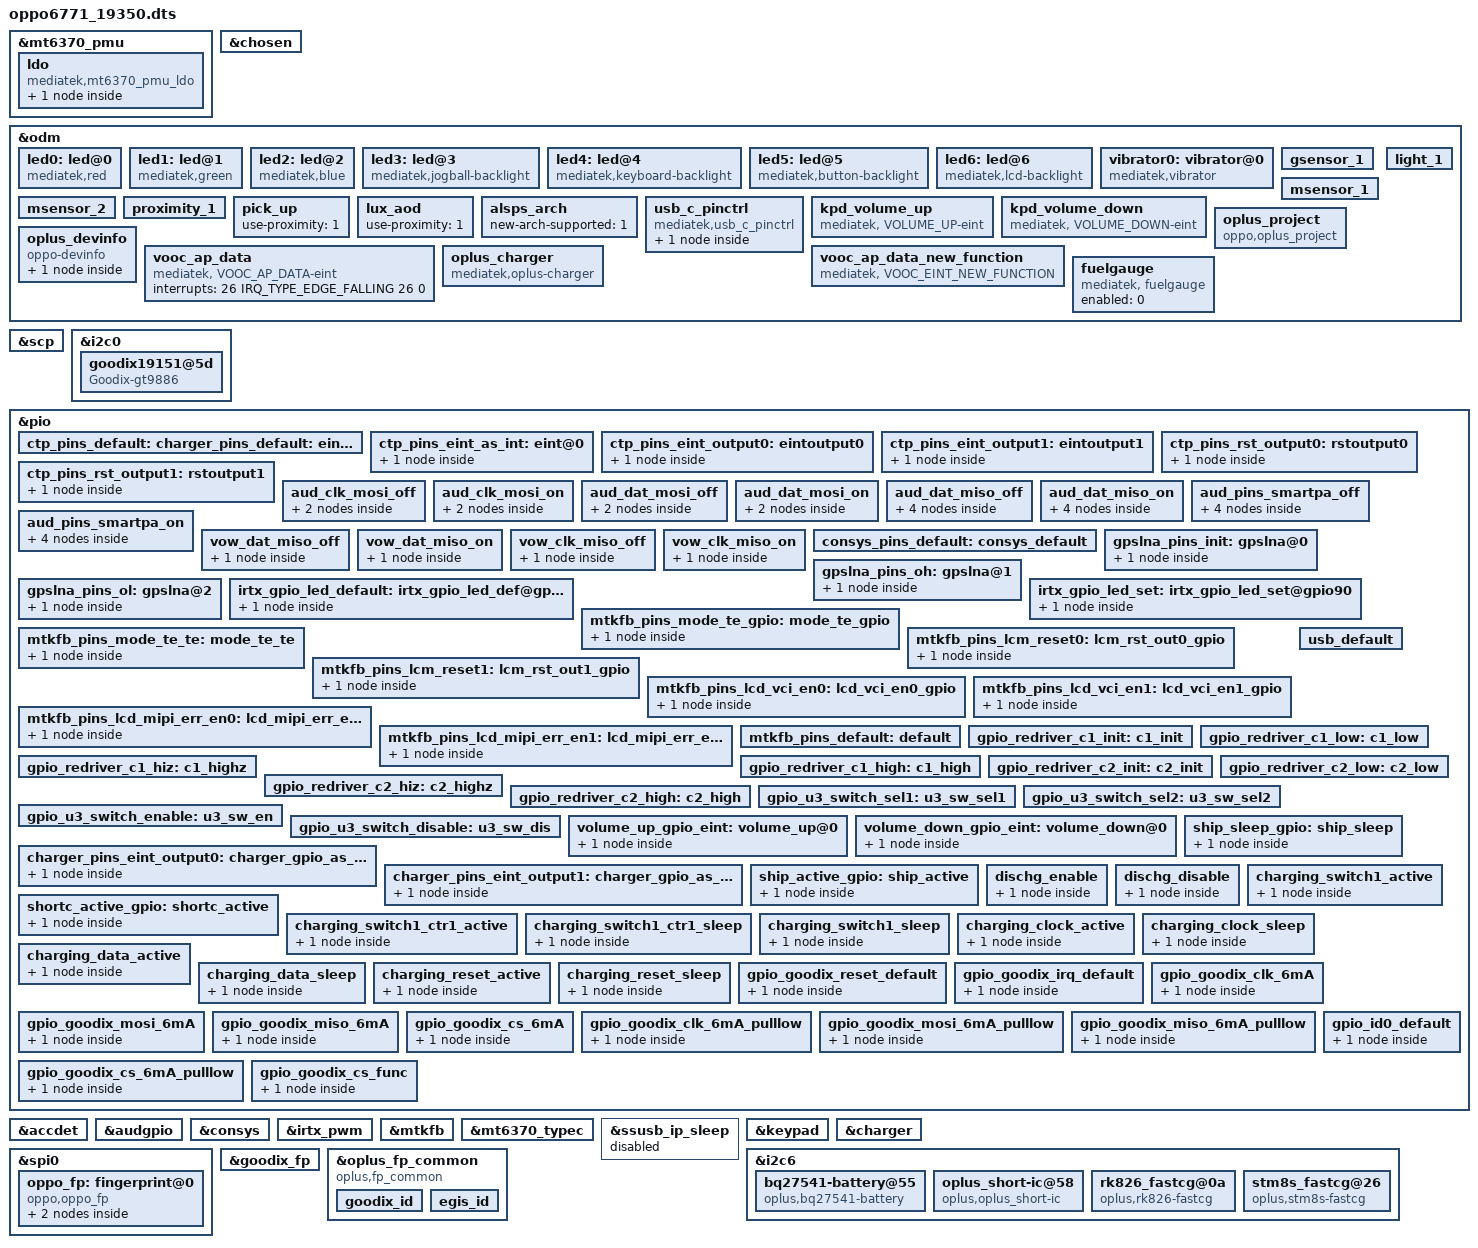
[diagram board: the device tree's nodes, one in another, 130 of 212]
/*
 * Mediatek's mt6771 SoC device tree source
 *
 * Copyright (C) 2016 MediaTek Inc.
 *
 * This program is free software; you can redistribute it and/or modify
 * it under the terms of the GNU General Public License version 2 as
 * published by the Free Software Foundation.
 *
 * This program is distributed in the hope that it will be useful,
 * but WITHOUT ANY WARRANTY; without even the implied warranty of
 * MERCHANTABILITY or FITNESS FOR A PARTICULAR PURPOSE.
 * See http://www.gnu.org/licenses/gpl-2.0.html for more details.
 */
/dts-v1/;
/plugin/;
#include <dt-bindings/interrupt-controller/irq.h>
#include <dt-bindings/interrupt-controller/arm-gic.h>
#include <dt-bindings/pinctrl/mt6771-pinfunc.h>

&mt6370_pmu {
	ldo {
		compatible = "mediatek,mt6370_pmu_ldo";
		interrupt-names = "ldo_oc";
		ldo_oms = <1>; /* 0: floating ; 1: discharge to ground for off mode */
		/* 0:  1 step/16us; 1 : 2 steps/16us; 2: 4 steps/16us; 3: 8steps/16us */
		/*ldo_vrc = <0>; */ /* to assign this  a value will also set en_vrc = 1 */

		ldo_vrc_lt = <1>; /* 0 : disable; 1: 10 us; 2: 20 us; 3: 40 us */
		mt6370_ldo {
			//#ifndef VENDOR_EDIT
			//regulator-name = "irtx_ldo"; /* change name by yourself */
			//#else
			regulator-name = "avdd"; /* for fingerprint*/
			//#endif /*VENDOR_EDIT*/
			regulator-min-microvolt = <3000000>;
			regulator-max-microvolt = <3000000>; /* max == min then apply_uV = 1 */
			/* regulator-microvolt-offset = < 0>; optional*/
			/* regulator-boot-on = "yes"; optional, exist = enabled */
			regulator-always-on = "yes"; /* optional, exist = enabled */
			/* regulator-ramp-delay = <100>; optional*/
		};
	};
};
/* chosen */
&chosen {
	/* fpga may has no lk, we need to specify display info here */
	/* fb buffer is reserved using this dts by memory node above */

	atag,videolfb-fb_base_l = <0x5e605000>;
	atag,videolfb-fb_base_h = <0x0>;
	atag,videolfb-islcmfound = <1>;
	atag,videolfb-islcm_inited = <0>;
	atag,videolfb-fps= <6000>;
	atag,videolfb-vramSize= <0x017bb000>;
	atag,videolfb-lcmname= "nt35595_fhd_dsi_cmd_truly_nt50358_drv";
};

&odm {
//#ifdef VENDOR_EDIT
#include "mediatek/bat_setting/oppo_17197_mt6771_battery_prop_ext.dtsi"
//endif
	led0:led@0 {
		compatible = "mediatek,red";
		led_mode = <0>;
		data = <1>;
		pwm_config = <0 0 0 0 0>;
	};
	led1:led@1 {
		compatible = "mediatek,green";
		led_mode = <0>;
		data = <1>;
		pwm_config = <0 0 0 0 0>;
	};
	led2:led@2 {
		compatible = "mediatek,blue";
		led_mode = <0>;
		data = <1>;
		pwm_config = <0 0 0 0 0>;
	};
	led3:led@3 {
		compatible = "mediatek,jogball-backlight";
		led_mode = <0>;
		data = <1>;
		pwm_config = <0 0 0 0 0>;
	};
	led4:led@4 {
		compatible = "mediatek,keyboard-backlight";
		led_mode = <0>;
		data = <1>;
		pwm_config = <0 0 0 0 0>;
	};
	led5:led@5 {
		compatible = "mediatek,button-backlight";
		led_mode = <0>;
		data = <1>;
		pwm_config = <0 0 0 0 0>;
	};
	led6:led@6 {
		compatible = "mediatek,lcd-backlight";
		/* #ifdef OPLUS_BUG_STABILITY */
		/* led_mode = <5>; */
		/* #else*/
		led_mode = <4>;
		/* #endif */ /* OPLUS_BUG_STABILITY */
		data = <1>;
		pwm_config = <0 1 0 0 0>;
	};
	vibrator0:vibrator@0 {
		compatible = "mediatek,vibrator";
		vib_timer = <30>;
		vib_limit = <0>;
		vib_vol= <11>;
	};
/* sensor start */
	/*
	enum {
		LIS3DH,
		LSM6DS3,
		BMI160,
		LIS2HH12,
		LSM6DSM,
		BMI2XY,
		LSM6DSO,
	};
	*/
	gsensor_1: gsensor_1 {
		status = "okay";
		sensor_name = <2>;//BMI160
		i2c_num = <1>;
		i2c_addr = <0x68>;
		direction = <7>;
		eint_num = <4>;
		step_count_7_en = <0>;
		config_miso = <0>;
		correct_y_bias = <0>;
	};

	/*
	enum {
		AKM09911,
		MMC3530,
		MMC5603,
		MXG4300,
	};
	*/
	msensor_1: msensor_1 {
		status = "okay";
		sensor_name = <1>;//MMC3530
		i2c_num = <1>;
		i2c_addr = <0x30>;
		direction = <2>;
		eint_num = <0>;
		libname = "mmc";
		soft-mag-parameter = <9997 0 103 1 54 0 108 1 1073 0 102 0 548 1 53 1 11493 0>;
	};
	msensor_2: msensor_2 {
		status = "okay";
		sensor_name = <0>;//AKM09911
		i2c_num = <1>;
		i2c_addr = <12>;
		direction = <0>;
		eint_num = <0>;
		libname = "akm";
		soft-mag-parameter = <199 81 100 63 93 113 1 69 217 53 152 58 161 164 1 249
			                       0 75 24 170 194 250 165 135 14 184 11>;
        };
	/*
	enum {
		TMD2725,
		APSD9922,
		STK3335,
		STK3331,
		STK2232,
		TCS3701,
		STK32600,
	};
	*/
	proximity_1: proximity_1 {
		status = "okay";
		sensor_name = <5>;//TCS3701
		i2c_num = <1>;
		i2c_addr = <57>;
		direction = <4>;
		eint_num = <7>;
		low_step = <300>;
		high_step = <400>;
		low_limit = <400>;
		high_limit = <600>;
		dirty_low_step = <180>;
		dirty_high_step = <250>;
		ps_dirty_limit = <1023>;
		ps_ir_limit = <500>;
		ps_adjust_min = <0>;
		ps_adjust_max = <600>;
		sampling_count = <5>;
		step_max = <400>;
		step_min = <110>;
		step_div = <1500>;
		anti_shake_delta = <80>;
		dynamic_cali_max = <1024>;
		raw2offset_radio = <20800>;
		offset_max = <250>;
		offset_range_min = <255>;
		offset_range_max = <255>;
		force_cali_limit = <2000>;
		cali_jitter_limit = <30>;
		cal_offset_margin = <120>;
	};
	light_1: light_1 {
		status = "okay";
		sensor_name = <5>;//TCS3701
		i2c_num = <1>;
		i2c_addr = <57>;
		direction = <4>;
		eint_num = <7>;
		als_ratio = <110>;
		als_type = <2>;
		als_buffer_length =<10>;
		device_name = "tcs3701";
	};
	pick_up: pick_up {
		status = "okay";
		use-proximity = <1>;
	};
	lux_aod: lux_aod {
		status = "okay";
		use-proximity = <1>;
	};
	alsps_arch: alsps_arch {
		status = "okay";
		new-arch-supported = <1>;
	};
/* sensor end */

	usb_c_pinctrl:usb_c_pinctrl {
		compatible = "mediatek,usb_c_pinctrl";
	};

       kpd_volume_up:kpd_volume_up {
               compatible = "mediatek, VOLUME_UP-eint";
               interrupt-parent = <&pio>;
               interrupts = <20 IRQ_TYPE_EDGE_FALLING 20 0>;
               debounce = <32000>;
               status = "okay";
       };

       kpd_volume_down:kpd_volume_down {
               compatible = "mediatek, VOLUME_DOWN-eint";
               interrupt-parent = <&pio>;
               interrupts = <94 IRQ_TYPE_EDGE_FALLING 94 0>;
               debounce = <32000>;
               status = "okay";
       };

	oplus_project:oplus_project {
		compatible = "oppo,oplus_project";
	};
	oplus_devinfo:oplus_devinfo {
		compatible = "oppo-devinfo";

		main-sub {
			compatible = "hw-match, main-sub";
			aboard-patterns = <0 0 0 0>;
			/*main board*/
			//match-projects = <20075 20076>;
		};
	};
	
		//#ifdef VENDOR_EDIT
	vooc_ap_data:vooc_ap_data {
		compatible = "mediatek, VOOC_AP_DATA-eint";
		interrupts = <26 IRQ_TYPE_EDGE_FALLING 26 0>;
	};
	vooc_ap_data_new_function:vooc_ap_data_new_function {
		compatible = "mediatek, VOOC_EINT_NEW_FUNCTION";
	};
	//#endif /*VENDOR_EDIT*/

	oplus_charger: oplus_charger {
		compatible = "mediatek,oplus-charger";
		pinctrl-names = "default", "charger_gpio_as_output_low", "charger_gpio_as_output_high",
				"ship_sleep", "ship_active", "dischg_enable", "dischg_disable";
		pinctrl-0 = <&charger_pins_default>;
		pinctrl-1 = <&charger_pins_eint_output0>;
		pinctrl-2 = <&charger_pins_eint_output1>;
		pinctrl-3 = <&ship_sleep_gpio>;
		pinctrl-4 = <&ship_active_gpio>;
		pinctrl-5 = <&dischg_enable>;
		pinctrl-6 = <&dischg_disable>;
		//pinctrl-5 = <&shortc_active_gpio>;

		//for oplus chg framework:
		qcom,pd_input_current_charger_ma = <3000>;
		qcom,input_current_charger_ma = <2000>;
		qcom,input_current_cdp_ma = <1500>;
		qcom,input_current_usb_ma = <500>;
		qcom,input_current_led_ma = <1200>;
		qcom,input_current_led_ma_forcmcc = <500>;
		qcom,input_current_camera_ma = <1200>;
		qcom,input_current_calling_ma = <1500>;
		qcom,input_current_led_ma_high = <1200>;
		qcom,input_current_led_ma_warm = <1500>;
		qcom,input_current_led_ma_normal = <2000>;
		qcom,led_warm_bat_decidegc = <350>;
		qcom,led_high_bat_decidegc = <370>;

		qcom,iterm_disabled = <0>;
		qcom,iterm_ma = <209>;
		qcom,recharge-mv = <100>;

		qcom,batt_capacity_mah = <4025>; /*typical capacity*/
		//qcom,batt_capacity_mah = <3975>; /*rated capacity*/

		qcom,removed_bat_decidegc = <190>;  /* < -19C */

		qcom,cold_bat_decidegc = <20>;  /* -3C ~ 0C */
		qcom,temp_cold_vfloat_mv = <3980>;
		qcom,temp_cold_fastchg_current_ma = <360>;

		qcom,little_cold_bat_decidegc = <0>;	/* 0C ~ 5C */
		qcom,temp_little_cold_vfloat_mv = <4435>;
		qcom,temp_little_cold_fastchg_current_ma_high = <1850>;
		qcom,temp_little_cold_fastchg_current_ma_low = <1100>;
		qcom,temp_little_cold_fastchg_current_ma = <1100>;
		qcom,pd_temp_little_cold_fastchg_current_ma_high = <1850>;
		qcom,pd_temp_little_cold_fastchg_current_ma_low = <1100>;

		qcom,cool_bat_decidegc = <50>;	/* 5C ~ 12C */
		qcom,temp_cool_vfloat_mv = <4435>;
		qcom,temp_cool_fastchg_current_ma_high = <2200>;
		qcom,temp_cool_fastchg_current_ma_low = <1850>;
		qcom,pd_temp_cool_fastchg_current_ma_high = <2550>;
		qcom,pd_temp_cool_fastchg_current_ma_low = <1850>;

		qcom,little_cool_bat_decidegc = <120>;	/* 12C ~ 16C */
		qcom,temp_little_cool_vfloat_mv = <4435>;
		qcom,temp_little_cool_fastchg_current_ma = <2200>;
		qcom,pd_temp_little_cool_fastchg_current_ma = <3300>;

		qcom,normal_bat_decidegc = <160>;	/* 16C ~ 45C */
		qcom,temp_normal_vfloat_mv = <4435>;
		qcom,temp_normal_fastchg_current_ma = <2200>;
		qcom,pd_temp_normal_fastchg_current_ma = <3300>;

		qcom,warm_bat_decidegc = <450>;		/* 45C ~ 53C */ /*8pin Bat Vooc project need add 3 degree C*/
		qcom,temp_warm_vfloat_mv = <4130>;
		qcom,temp_warm_fastchg_current_ma = <1100>;
		qcom,temp_warm_fastchg_current_ma_led_on = <500>;
		qcom,pd_temp_warm_fastchg_current_ma = <1100>;

		qcom,hot_bat_decidegc = <530>;  /* > 53C */

		qcom,non_standard_vfloat_mv = <3980>;
		qcom,non_standard_fastchg_current_ma = <512>;

		qcom,short_c_bat_cv_mv = <4330>;
		qcom,short_c_bat_vfloat_mv = <3800>;
		qcom,short_c_bat_fastchg_current_ma = <512>;
		qcom,short_c_bat_vfloat_sw_limit = <3750>;

		qcom,cold_vfloat_sw_limit = <3930>;
		qcom,little_cold_vfloat_sw_limit = <4385>;
		qcom,cool_vfloat_sw_limit = <4385>;
		qcom,little_cool_vfloat_sw_limit = <4385>;
		qcom,normal_vfloat_sw_limit = <4385>;
		qcom,warm_vfloat_sw_limit = <4080>;
		qcom,non_standard_vfloat_sw_limit = <3930>;

		qcom,max_chg_time_sec = <36000>;
		qcom,charger_hv_thr = <5800>;
		qcom,charger_lv_thr = <3400>;
		qcom,vbatt_full_thr = <4450>;
		qcom,vbatt_hv_thr = <4550>;
	
		qcom,vfloat_step_mv = <10>;
		qcom,non_standard_vfloat_over_sw_limit = <3990>;
		qcom,cold_vfloat_over_sw_limit = <3990>;
		qcom,little_cold_vfloat_over_sw_limit = <4445>;
		qcom,cool_vfloat_over_sw_limit = <4445>;
		qcom,little_cool_vfloat_over_sw_limit = <4445>;
		qcom,normal_vfloat_over_sw_limit = <4445>;
		qcom,warm_vfloat_over_sw_limit = <4140>;

		qcom,vbatt_power_off = <3300>;
		qcom,vbatt_soc_1 = <3410>;
		qcom,vooc_project = <1>;
		qcom,vbatt_num = <1>;

		qcom,normal_vterm_hw_inc = <13>;
		qcom,non_normal_vterm_hw_inc = <13>;

		qcom,ff1_normal_fastchg_ma = <1500>;
		qcom,ff1_warm_fastchg_ma = <1500>;
		qcom,ffc2_normal_fastchg_ma = <1100>;/*12C~35c*/
		qcom,ffc2_warm_fastchg_ma = <1200>;/*35C~40c*/
		qcom,ffc2_temp_warm_decidegc = <350>;
		qcom,ffc2_temp_high_decidegc = <400>;
		qcom,ffc2_temp_low_decidegc = <120>;
		qcom,ff1_exit_step_ma = <600>;
		qcom,ff1_warm_exit_step_ma = <500>;
		qcom,ffc2_exit_step_ma = <200>;
		qcom,ffc2_warm_exit_step_ma = <200>;

		qcom,ffc_normal_vfloat_sw_limit = <4475>;
		qcom,ffc2_normal_vfloat_sw_limit = <4475>;
		qcom,ffc_temp_normal_vfloat_mv = <4550>;
		qcom,ffc_normal_vfloat_over_sw_limit = <4550>;

		qcom,default_iterm_ma = <209>;
		qcom,default_temp_normal_fastchg_current_ma = <2200>;
		qcom,default_normal_vfloat_sw_limit = <4385>;
		qcom,default_temp_normal_vfloat_mv = <4435>;
		qcom,default_normal_vfloat_over_sw_limit = <4445>;

		//for 2nd chip:
		qcom,iterm_ma_2nd = <300>;
		qcom,recharge-mv_2nd = <121>;

		qcom,temp_little_cold_vfloat_mv_2nd = <4391>;	/* 0C ~ 5C */
		qcom,temp_cool_vfloat_mv_2nd = <4391>;	/* 5C ~ 12C */
		qcom,temp_little_cool_vfloat_mv_2nd = <4391>;	/* 12C ~ 16C */
		qcom,temp_normal_vfloat_mv_2nd = <4391>;	/* 16C ~ 45C */

		qcom,little_cold_vfloat_over_sw_limit_2nd = <4395>;
		qcom,cool_vfloat_over_sw_limit_2nd = <4395>;
		qcom,little_cool_vfloat_over_sw_limit_2nd = <4395>;
		qcom,normal_vfloat_over_sw_limit_2nd = <4445>;

		qcom,default_iterm_ma_2nd = <300>;
		qcom,default_temp_normal_vfloat_mv_2nd = <4391>;
		qcom,default_normal_vfloat_over_sw_limit_2nd = <4445>;

		//for control:
		//qcom,suspend_after_full;
		qcom,check_batt_full_by_sw;
		qcom,external_gauge;
		qcom,chg_ctrl_by_calling;
		qcom,chg_ctrl_by_lcd;
		qcom,chg_ctrl_by_camera;
		qcom,sw_vfloat_over_protect_enable;
		qcom,ffc_support;

		//GPIO config:
		qcom,chargerid_switch-gpio = <&pio 97 0x00>;
		qcom,ship-gpio = <&pio 155 0x00>;
		qcom,dischg-gpio = <&pio 17 0x00>;
		//qcom,shortc-gpio = <&pio 77 0x00>;
	};
	
//#ifdef VENDOR_EDIT
	fuelgauge: fuelgauge {
		compatible = "mediatek, fuelgauge";
	};
//#endif
};

&scp {
	core_1 = "enable";
	scp_sramSize = <0x00080000>;     /* scp_A_sram_size */
};
//#ifdef OPLUS_FEATURE_TP_BASIC
&i2c0 {
	status = "okay";
	goodix19151@5d {
		compatible = "Goodix-gt9886";
		reg = <0x5d>;
		chip-name = "GT9886";

		/* Interrupt && Irq-gpio */
		//interrupt-parent = <&tlmm>;
		//interrupts = <1 0x2002>;
		interrupt-parent = <&pio>;
		interrupts = <1 IRQ_TYPE_EDGE_FALLING 1 0>;

		/* Power Config */
		enable2v8_gpio = <&pio 159 0x1>;
		//vdd_2v8-supply = <&mt_pmic_vmch_ldo_reg>;
		//vcc_1v8-supply = <&pm660_l14>;
		//vdd_2v8_volt = <2950000>;

		/* Other HW Resource */
		//irq-gpio = <&tlmm 1 0x2008>;
		irq-gpio = <&pio 1 0x2002>;
		//reset-gpio = <&tlmm 58 0x1>;
		reset-gpio = <&pio 150 0>;
		pinctrl-names = "default";
		//pinctrl-0 = <&ts_int_active &ts_reset_active>;

		vid_len = <2>;
		tp_type = <8>;
		// type of tp_dev ,TP-SAMSUNG = 8;
		platform_support_project = <19350 19352 19355>;
		platform_support_project_dir = <19151 19151 19151>;
		platform_support_project_commandline = "default_commandline", "default_commandline", "default_commandline";

		touchpanel,max-num-support = <10>;
		touchpanel,tx-rx-num = <15 34>;
		touchpanel,panel-coords = <1080 2400>;
		touchpanel,display-coords = <1080 2400>;
		touchpanel,touchmajor-limit = <0 54>;

		/* SW Support Feature Control */
		register-is-16bit;
		black_gesture_support;
		single_tap_support;
		fw_edge_limit_support;
		pressure_report_support;
		charger_pump_support;
		game_switch_support;
		smart_gesture_support;
		fw_update_app_support;
		fingerprint_underscreen_support;
		esd_handle_support;
		/*
		 *Virtual Key Config:
		 *1:touchpanel,button-type: <virtualkey_type  supportted_button-map>
		 *virtualkey_type:
		 *Type 1: using board_properties
		 *Type 2: using same IC (button zone&& touch zone are seprate)
		 *Type 3: using diffrent IC (button zone&& touch zone are seprate)
		 *Type 4: No need of virtual key process
		 *supportted_button-map:select|menu|home|back
		 *
		 *2:touchpanel,button-map
		 *type (X1,Y1)(X2,Y2)(X3,Y3)(Width_X,Hight_Y)--Only when button-type is 0
		 */
		touchpanel,button-type = <4>;
		touchpanel.button-TRx = <0 0>;
	};
};
//#endif
/* TOUCH start */
/*&touch {
	tpd-resolution = <1080 1920>;
	use-tpd-button = <0>;
	tpd-key-num = <3>;
	tpd-key-local= <139 172 158 0>;
	tpd-key-dim-local = <90 883 100 40 230 883 100 40 370 883 100 40 0 0 0 0>;
	tpd-max-touch-num = <5>;
	tpd-filter-enable = <1>;
	tpd-filter-pixel-density = <146>;
	tpd-filter-custom-prameters = <0 0 0 0 0 0 0 0 0 0 0 0>;
	tpd-filter-custom-speed = <0 0 0>;
	pinctrl-names = "default", "state_eint_as_int",
		"state_eint_output0", "state_eint_output1",
		"state_rst_output0", "state_rst_output1";
	pinctrl-0 = <&ctp_pins_default>;
	pinctrl-1 = <&ctp_pins_eint_as_int>;
	pinctrl-2 = <&ctp_pins_eint_output0>;
	pinctrl-3 = <&ctp_pins_eint_output1>;
	pinctrl-4 = <&ctp_pins_rst_output0>;
	pinctrl-5 = <&ctp_pins_rst_output1>;
	status = "okay";
};*/
&pio {
	ctp_pins_default: eint0default {
	};
	ctp_pins_eint_as_int: eint@0 {
		pins_cmd_dat {
			pinmux = <PINMUX_GPIO1__FUNC_GPIO1>;
			slew-rate = <0>;
			bias-disable;
		};
	};
	ctp_pins_eint_output0: eintoutput0 {
		pins_cmd_dat {
			pinmux = <PINMUX_GPIO1__FUNC_GPIO1>;
			slew-rate = <1>;
			output-low;
		};
	};
	ctp_pins_eint_output1: eintoutput1 {
		pins_cmd_dat {
			pinmux = <PINMUX_GPIO1__FUNC_GPIO1>;
			slew-rate = <1>;
			output-high;
		};
	};
	ctp_pins_rst_output0: rstoutput0 {
		pins_cmd_dat {
			pinmux = <PINMUX_GPIO2__FUNC_GPIO2>;
			slew-rate = <1>;
			output-low;
		};
	};
	ctp_pins_rst_output1: rstoutput1 {
		pins_cmd_dat {
			pinmux = <PINMUX_GPIO2__FUNC_GPIO2>;
			slew-rate = <1>;
			output-high;
		};
	};
};
/* TOUCH end */

/* accdet start */
&accdet {
	/* accdet micbias voltage: 0x07,2.7v;0x05,2.5v;0x02,1.9v */
	accdet-mic-vol = <6>;
	headset-mode-setting = <0x500 0x500 1 0x1f0 0x800 0x800 0x20 0x44>;
	accdet-plugout-debounce = <1>;
	/*1:ACC mode, 2:low cost without in bias, 6:low cost with in bias*/
	accdet-mic-mode = <1>;
	/* eint_level_trigger: 8,LEVEL_LOW(default);4,LEVEL_HIGH;others,LEVEL_LOW */
	headset-eint-level-pol = <8>;
	/*0--MD_MAX--UP_MAX--DW_MAX*/
	headset-three-key-threshold = <0 80 220 400>;
	headset-three-key-threshold-CDD = <0 121 192 600>;
	/*0--MD_MAX--VOICE_MAX--UP_MAX--DW_MAX*/
	headset-four-key-threshold = <0 58 121 192 400>;
	status = "okay";
};
/* accdet end */

/* AUDIO GPIO standardization */
&audgpio {
	pinctrl-names = "aud_clk_mosi_off",
			"aud_clk_mosi_on",
			"aud_dat_mosi_off",
			"aud_dat_mosi_on",
			"aud_dat_miso_off",
			"aud_dat_miso_on",
			"aud_smartpa_off",
			"aud_smartpa_on",
			"vow_dat_miso_off",
			"vow_dat_miso_on",
			"vow_clk_miso_off",
			"vow_clk_miso_on";
	pinctrl-0 = <&aud_clk_mosi_off>;
	pinctrl-1 = <&aud_clk_mosi_on>;
	pinctrl-2 = <&aud_dat_mosi_off>;
	pinctrl-3 = <&aud_dat_mosi_on>;
	pinctrl-4 = <&aud_dat_miso_off>;
	pinctrl-5 = <&aud_dat_miso_on>;
	pinctrl-6 = <&aud_pins_smartpa_off>;
	pinctrl-7 = <&aud_pins_smartpa_on>;
	pinctrl-8 = <&vow_dat_miso_off>;
	pinctrl-9 = <&vow_dat_miso_on>;
	pinctrl-10 = <&vow_clk_miso_off>;
	pinctrl-11 = <&vow_clk_miso_on>;
	status = "okay";
};

&pio {
	aud_clk_mosi_off: aud_clk_mosi_off {
		pins_cmd0_dat {
			pinmux = <PINMUX_GPIO136__FUNC_GPIO136>;
			input-enable;
			bias-pull-down;
		};
		pins_cmd1_dat {
			pinmux = <PINMUX_GPIO137__FUNC_GPIO137>;
			input-enable;
			bias-pull-down;
		};
	};

	aud_clk_mosi_on: aud_clk_mosi_on {
		pins_cmd0_dat {
			pinmux = <PINMUX_GPIO136__FUNC_AUD_CLK_MOSI>;
			input-schmitt-enable;
			bias-disable;
		};
		pins_cmd1_dat {
			pinmux = <PINMUX_GPIO137__FUNC_AUD_SYNC_MOSI>;
			input-schmitt-enable;
			bias-disable;
		};
	};

	aud_dat_mosi_off: aud_dat_mosi_off {
		pins_cmd0_dat {
			pinmux = <PINMUX_GPIO138__FUNC_GPIO138>;
			input-enable;
			bias-disable;
		};
		pins_cmd1_dat {
			pinmux = <PINMUX_GPIO139__FUNC_GPIO139>;
			input-enable;
			bias-pull-down;
		};
	};

	aud_dat_mosi_on: aud_dat_mosi_on {
		pins_cmd0_dat {
			pinmux = <PINMUX_GPIO138__FUNC_AUD_DAT_MOSI0>;
			input-schmitt-enable;
			bias-disable;
		};
		pins_cmd1_dat {
			pinmux = <PINMUX_GPIO139__FUNC_AUD_DAT_MOSI1>;
			input-schmitt-enable;
			bias-disable;
		};
	};

	aud_dat_miso_off: aud_dat_miso_off {
		pins_cmd0_dat {
			pinmux = <PINMUX_GPIO140__FUNC_GPIO140>;
			input-enable;
			bias-disable;
		};
		pins_cmd1_dat {
			pinmux = <PINMUX_GPIO141__FUNC_GPIO141>;
			input-enable;
			bias-disable;
		};
		pins_cmd2_dat {
			pinmux = <PINMUX_GPIO142__FUNC_GPIO142>;
			input-enable;
			bias-disable;
		};
		pins_cmd3_dat {
			pinmux = <PINMUX_GPIO143__FUNC_GPIO143>;
			input-enable;
			bias-disable;
		};
	};

	aud_dat_miso_on: aud_dat_miso_on {
		pins_cmd0_dat {
			pinmux = <PINMUX_GPIO140__FUNC_AUD_CLK_MISO>;
			input-schmitt-enable;
			bias-disable;
		};
		pins_cmd1_dat {
			pinmux = <PINMUX_GPIO141__FUNC_AUD_SYNC_MISO>;
			input-schmitt-enable;
			bias-disable;
		};
		pins_cmd2_dat {
			pinmux = <PINMUX_GPIO142__FUNC_AUD_DAT_MISO0>;
			input-schmitt-enable;
			bias-disable;
		};
		pins_cmd3_dat {
			pinmux = <PINMUX_GPIO143__FUNC_AUD_DAT_MISO1>;
			input-schmitt-enable;
			bias-disable;
		};
	};

	aud_pins_smartpa_off: aud_pins_smartpa_off {
		pins_cmd0_dat {
			pinmux = <PINMUX_GPIO174__FUNC_GPIO174>;
		};
		pins_cmd1_dat {
			pinmux = <PINMUX_GPIO170__FUNC_GPIO170>;
		};
		pins_cmd2_dat {
			pinmux = <PINMUX_GPIO171__FUNC_GPIO171>;
		};
		pins_cmd3_dat {
			pinmux = <PINMUX_GPIO172__FUNC_GPIO172>;
		};
	};

	aud_pins_smartpa_on: aud_pins_smartpa_on {
		pins_cmd0_dat {
			pinmux = <PINMUX_GPIO174__FUNC_I2S0_DI>;
		};
		pins_cmd1_dat {
			pinmux = <PINMUX_GPIO170__FUNC_I2S3_BCK>;
		};
		pins_cmd2_dat {
			pinmux = <PINMUX_GPIO171__FUNC_I2S3_LRCK>;
		};
		pins_cmd3_dat {
			pinmux = <PINMUX_GPIO172__FUNC_I2S3_DO>;
		};
	};

	vow_dat_miso_off: vow_dat_miso_off {
		pins_cmd1_dat {
			pinmux = <PINMUX_GPIO142__FUNC_GPIO142>;
			input-enable;
			bias-pull-down;
		};
	};

	vow_dat_miso_on: vow_dat_miso_on {
		pins_cmd1_dat {
			pinmux = <PINMUX_GPIO142__FUNC_VOW_DAT_MISO>;
			input-schmitt-enable;
			bias-disable;
		};
	};

	vow_clk_miso_off: vow_clk_miso_off {
		pins_cmd3_dat {
			pinmux = <PINMUX_GPIO143__FUNC_GPIO143>;
			input-enable;
			bias-pull-down;
		};
	};

	vow_clk_miso_on: vow_clk_miso_on {
		pins_cmd3_dat {
			pinmux = <PINMUX_GPIO143__FUNC_VOW_CLK_MISO>;
			input-schmitt-enable;
			bias-disable;
		};
	};
};
/* AUDIO end */

/* CONSYS GPIO standardization */
&pio {
	consys_pins_default: consys_default {
	};
	gpslna_pins_init: gpslna@0 {
		pins_cmd_dat {
			pinmux = <PINMUX_GPIO169__FUNC_GPIO169>;
			//#ifndef VENDOR_EDIT
			//modify for: [GPS_LNA gpio's output direction is out]
			/*
			slew-rate = <0>;
			*/
			//#else /* VENDOR_EDIT */
			slew-rate = <1>;
			//#endif /* VENDOR_EDIT */
			bias-disable;
			output-low;
		};
	};
	gpslna_pins_oh: gpslna@1 {
		pins_cmd_dat {
			pinmux = <PINMUX_GPIO169__FUNC_GPIO169>;
			slew-rate = <1>;
			output-high;
		};
	};
	gpslna_pins_ol: gpslna@2 {
		pins_cmd_dat {
			pinmux = <PINMUX_GPIO169__FUNC_GPIO169>;
			slew-rate = <1>;
			output-low;
		};
	};
};
&consys {
	pinctrl-names = "default", "gps_lna_state_init", "gps_lna_state_oh", "gps_lna_state_ol";
	pinctrl-0 = <&consys_pins_default>;
	pinctrl-1 = <&gpslna_pins_init>;
	pinctrl-2 = <&gpslna_pins_oh>;
	pinctrl-3 = <&gpslna_pins_ol>;
	status = "okay";
};
/* CONSYS end */

/* IRTX GPIO Start */
&irtx_pwm {
	pinctrl-names = "irtx_gpio_led_default", "irtx_gpio_led_set";
	pinctrl-0 = <&irtx_gpio_led_default>;
	pinctrl-1 = <&irtx_gpio_led_set>;
	status = "okay";
};
&pio {
	/* IRTX GPIO Settings -Start */
	/* default: GPIO0, output, high */
	irtx_gpio_led_default:irtx_gpio_led_def@gpio90 {
		pins_cmd_dat {
			pinmux = <PINMUX_GPIO90__FUNC_GPIO90>;
			slew-rate = <1>;
			bias-disable;
			output-low;
			input-schmitt-enable = <0>;
		};
	};

	irtx_gpio_led_set:irtx_gpio_led_set@gpio90 {
		pins_cmd_dat {
			pinmux = <PINMUX_GPIO90__FUNC_PWM_A>;
			slew-rate = <1>;
			output-high;
		};
	};
}; /* IRTX GPIO Settings -End */


/* #ifdef OPLUS_BUG_STABILITY */
&pio {
	mtkfb_pins_mode_te_gpio: mode_te_gpio {
		pins_cmd_dat {
			pinmux = <PINMUX_GPIO44__FUNC_GPIO44>;
	};
		};

	mtkfb_pins_mode_te_te: mode_te_te {
		pins_cmd_dat {
			pinmux = <PINMUX_GPIO44__FUNC_DSI_TE>;
		};
	};

	mtkfb_pins_lcm_reset0: lcm_rst_out0_gpio {
		pins_cmd_dat {
			pinmux = <PINMUX_GPIO45__FUNC_GPIO45>;
			slew-rate = <1>;
			output-low;
		};
	};

	mtkfb_pins_lcm_reset1: lcm_rst_out1_gpio {
		pins_cmd_dat {
			pinmux = <PINMUX_GPIO45__FUNC_GPIO45>;
			slew-rate = <1>;
			output-high;
		};
	};

	mtkfb_pins_lcd_vci_en0: lcd_vci_en0_gpio {
		pins_cmd_dat {
			pinmux = <PINMUX_GPIO46__FUNC_GPIO46>;
			slew-rate = <1>;
			output-low;
		};
	};

	mtkfb_pins_lcd_vci_en1: lcd_vci_en1_gpio {
		pins_cmd_dat {
			pinmux = <PINMUX_GPIO46__FUNC_GPIO46>;
			slew-rate = <1>;
			output-high;
		};
	};

	mtkfb_pins_lcd_mipi_err_en0: lcd_mipi_err_en0_gpio {
		pins_cmd_dat {
			pinmux = <PINMUX_GPIO9__FUNC_GPIO9>;
			slew-rate = <1>;
			output-low;
		};
	};

	mtkfb_pins_lcd_mipi_err_en1: lcd_mipi_err_en1_gpio {
		pins_cmd_dat {
			pinmux = <PINMUX_GPIO9__FUNC_GPIO9>;
			slew-rate = <1>;
			output-high;
		};
	};


	mtkfb_pins_default: default {
};
};

&mtkfb {
	pinctrl-names = "default", "mode_te_gpio", "mode_te_te", "lcm_rst_out0_gpio",
	"lcm_rst_out1_gpio", "lcd_vci_en0_gpio", "lcd_vci_en1_gpio",
	"lcd_mipi_err_en0_gpio", "lcd_mipi_err_en1_gpio";
	pinctrl-0 = <&mtkfb_pins_default>;
	pinctrl-1 = <&mtkfb_pins_mode_te_gpio>;
	pinctrl-2 = <&mtkfb_pins_mode_te_te>;
	pinctrl-3 = <&mtkfb_pins_lcm_reset0>;
	pinctrl-4 = <&mtkfb_pins_lcm_reset1>;
	pinctrl-5 = <&mtkfb_pins_lcd_vci_en0>;
	pinctrl-6 = <&mtkfb_pins_lcd_vci_en1>;
	pinctrl-7 = <&mtkfb_pins_lcd_mipi_err_en0>;
	pinctrl-8 = <&mtkfb_pins_lcd_mipi_err_en1>;
	status = "okay";
	oppo_display_elevenbits_support;
};
//#ifdef VENDOR_EDIT
&fuelgauge{
	enabled = <0>;
};
//#endif

//#ifdef VENDOR_EDIT
/*&i2c5 {

	bq25601d-charger@6b {
		status = "okay";
		compatible = "oplus,bq25601d-charger";
		reg = <0x6b>;
		chip-name = "BQ25601D";
		interrupt-parent = <&pio>;
		interrupts = <91 IRQ_TYPE_EDGE_FALLING 91 0>;
		chg-irq-gpio = <&pio 91 0x2002>;
	};

	bq25890h-charger@6a {
		status = "okay";
		compatible = "oplus,bq25890h-charger";
		reg = <0x6a>;
		chip-name = "BQ25890H";
		interrupt-parent = <&pio>;
		interrupts = <91 IRQ_TYPE_EDGE_FALLING 91 0>;
		chg-irq-gpio = <&pio 91 0x2002>;
	};
};*/
&mt6370_pmu {
//#ifdef VENDOR_EDIT
	//mt6370,intr_gpio_num = <10>; /* direct defined GPIO num */
	//mt6370,intr_gpio = <&pio 10 0x0>;
//#else
	mt6370,intr_gpio_num = <91>; /* direct defined GPIO num */
	mt6370,intr_gpio = <&pio 91 0x0>;
//#endif
};

&mt6370_typec {
	mt6370pd,intr_gpio_num = <41>; /* direct defined GPIO num */
	mt6370pd,intr_gpio = <&pio 41 0x0>;
//#ifdef VENDOR_EDIT
	mt-tcpc,role_def = <0>;
//#endif
};

//#ifdef VENDOR_EDIT
&ssusb_ip_sleep {
	status = "disabled";
};
//#endif /*VENDOR_EDIT*/

/* USB TYPEC GPIO start */
&pio {
	usb_default: usb_default {
	};
/*
	gpio_redriver_c1_init: c1_init {
		pins_cmd_dat {
			pinmux = <PINMUX_GPIO18__FUNC_GPIO18>;
			slew-rate = <1>;
			output-low;
		};
	};

	gpio_redriver_c1_low: c1_low {
		pins_cmd_dat {
			pinmux = <PINMUX_GPIO18__FUNC_GPIO18>;
			slew-rate = <1>;
			output-low;
		};
	};

	gpio_redriver_c1_hiz: c1_highz {
		pins_cmd_dat {
			pinmux = <PINMUX_GPIO18__FUNC_GPIO18>;
			slew-rate= <0>;
			bias-disable;
		};
	};

	gpio_redriver_c1_high: c1_high {
		pins_cmd_dat {
			pinmux = <PINMUX_GPIO18__FUNC_GPIO18>;
			slew-rate = <1>;
			output-high;
		};
	};

	gpio_redriver_c2_init: c2_init {
		pins_cmd_dat {
			pinmux = <PINMUX_GPIO17__FUNC_GPIO17>;
			slew-rate = <1>;
			output-low;
		};
	};

	gpio_redriver_c2_low: c2_low {
		pins_cmd_dat {
			pinmux = <PINMUX_GPIO17__FUNC_GPIO17>;
			slew-rate = <1>;
			output-low;
		};
	};

	gpio_redriver_c2_hiz: c2_highz {
		pins_cmd_dat {
			pinmux = <PINMUX_GPIO17__FUNC_GPIO17>;
			slew-rate= <0>;
			bias-disable;
		};
	};

	gpio_redriver_c2_high: c2_high {
		pins_cmd_dat {
			pinmux = <PINMUX_GPIO17__FUNC_GPIO17>;
			slew-rate = <1>;
			output-high;
		};
	};

	gpio_u3_switch_sel1: u3_sw_sel1 {
		pins_cmd_dat {
			pinmux = <PINMUX_GPIO177__FUNC_GPIO177>;
			slew-rate = <1>;
			output-low;
		};
	};

	gpio_u3_switch_sel2: u3_sw_sel2 {
		pins_cmd_dat {
			pinmux = <PINMUX_GPIO177__FUNC_GPIO177>;
			slew-rate = <1>;
			output-high;
		};
	};
*/
//#else
	gpio_redriver_c1_init: c1_init {
	};

	gpio_redriver_c1_low: c1_low {
	};

	gpio_redriver_c1_hiz: c1_highz {
	};

	gpio_redriver_c1_high: c1_high {
	};

	gpio_redriver_c2_init: c2_init {
	};

	gpio_redriver_c2_low: c2_low {
	};

	gpio_redriver_c2_hiz: c2_highz {
	};

	gpio_redriver_c2_high: c2_high {
	};

	gpio_u3_switch_sel1: u3_sw_sel1 {
	};

	gpio_u3_switch_sel2: u3_sw_sel2 {
	};
//#endif /*VENDOR_EDIT*/
	gpio_u3_switch_enable: u3_sw_en {
	};

	gpio_u3_switch_disable: u3_sw_dis {
	};
};

&usb_c_pinctrl {
	pinctrl-names = "usb_default",
		"redrv_c1_init",
		"redrv_c1_low",
		"redrv_c1_hiz",
		"redrv_c1_high",
		"redrv_c2_init",
		"redrv_c2_low",
		"redrv_c2_hiz",
		"redrv_c2_high",
		"switch_sel1",
		"switch_sel2",
		"switch_enable",
		"switch_disable";

	pinctrl-0 = <&usb_default>;
	pinctrl-1 = <&gpio_redriver_c1_init>;
	pinctrl-2 = <&gpio_redriver_c1_low>;
	pinctrl-3 = <&gpio_redriver_c1_hiz>;
	pinctrl-4 = <&gpio_redriver_c1_high>;
	pinctrl-5 = <&gpio_redriver_c2_init>;
	pinctrl-6 = <&gpio_redriver_c2_low>;
	pinctrl-7 = <&gpio_redriver_c2_hiz>;
	pinctrl-8 = <&gpio_redriver_c2_high>;
	pinctrl-9 = <&gpio_u3_switch_sel1>;
	pinctrl-10 = <&gpio_u3_switch_sel2>;
	pinctrl-11 = <&gpio_u3_switch_enable>;
	pinctrl-12 = <&gpio_u3_switch_disable>;
	status = "okay";

	usb_switch-data {
		en_pin_num = <0>;
		en_pin_val = <0>; /*DISABLE=0 ENABLE=1*/
		sel_pin_num = <177>;
		sel_pin_val = <1>; /*CC1=1, CC2=2*/
		c1_pin_num = <18>;
		c1_pin_val = <2>; /*Low=0, HighZ=1, High=2*/
		c2_pin_num = <17>;
		c2_pin_val = <1>;
	};
};
/* USB TYPEC GPIO end */

//#ifdef VENDOR_EDIT
&keypad {
	keypad,volume-up	= <&pio 20 0x00>;
	keypad,volume-down	= <&pio 94 0x00>;
	pinctrl-names = "volume_up_as_int", "volume_down_as_int";
	pinctrl-0 = <&volume_up_gpio_eint>;
	pinctrl-1 = <&volume_down_gpio_eint>;
	status = "okay";
};

&pio {
	volume_up_gpio_eint:volume_up@0{
		pins_cmd_dat {
			pinmux = <PINMUX_GPIO20__FUNC_GPIO20>;
			slew-rate = <0>;  /*direction 0:in, 1:out*/
			bias-pull-up = <00>;
			input-enable;
		};
	};
	volume_down_gpio_eint:volume_down@0{
		pins_cmd_dat {
			pinmux = <PINMUX_GPIO94__FUNC_GPIO94>;
			slew-rate = <0>;  /*direction 0:in, 1:out*/
			bias-pull-up = <00>;
			input-enable;
		};
	};
};
//#endif /*VENDOR_EDIT*/

&charger {
	algorithm_name = "DualSwitchCharging";
	chg1_ta_ac_charger_current = <2000000>;
	chg2_ta_ac_charger_current = <2000000>;
};
&pio {
	charger_pins_default: eint0default {
	};
	charger_pins_eint_output0: charger_gpio_as_output_low {
		pins_cmd_dat {
			pinmux = <PINMUX_GPIO97__FUNC_GPIO97>;
			slew-rate = <1>;
			output-low;
		};
	};
	charger_pins_eint_output1: charger_gpio_as_output_high {
		pins_cmd_dat {
			pinmux = <PINMUX_GPIO97__FUNC_GPIO97>;
			slew-rate = <1>;
			output-high;
		};
	};

	ship_sleep_gpio: ship_sleep {
		pins_cmd_dat {
			pinmux = <PINMUX_GPIO155__FUNC_GPIO155>;
			slew-rate = <1>;
			output-low;
		};
	};
	ship_active_gpio: ship_active {
		pins_cmd_dat {
			pinmux = <PINMUX_GPIO155__FUNC_GPIO155>;
			slew-rate = <1>;
			output-high;
		};
	};
	dischg_enable: dischg_enable {
		pins_cmd_dat {
			pinmux = <PINMUX_GPIO17__FUNC_GPIO17>;
			slew-rate = <1>;//0:input direction 1:output direction
			bias-pull-up = <00>;
			output-high;
		};
	};
	dischg_disable: dischg_disable {
		pins_cmd_dat {
			pinmux = <PINMUX_GPIO17__FUNC_GPIO17>;
			slew-rate = <1>;
			bias-pull-down = <00>;
			output-low;
		};
	};
	shortc_active_gpio: shortc_active {
		pins_cmd_dat {
			pinmux = <PINMUX_GPIO77__FUNC_GPIO77>;
			input-enable;
			slew-rate = <0>;
			bias-pull-up;
		};
	};
};

//#ifdef VENDOR_EDIT
&i2c6 {
	bq27541-battery@55 {
		status = "okay";
		compatible = "oplus,bq27541-battery";
		reg = <0x55 0>;
		qcom,modify-soc-smooth;
	};

	oplus_short-ic@58 {
		status = "okay";
		compatible = "oplus,oplus_short-ic";
		reg = <0x58>;
		qcom,modify-soc-smooth;
	};

	rk826_fastcg@0a{
		status = "okay";
		compatible = "oplus,rk826-fastcg";
		reg = <0x0a 0>;
		qcom,vooc-low-temp = <120>;
		qcom,oplus_batt_4400mv;
		qcom,vooc_fw_update_newmethod;
		qcom,vooc-fw-type = <1>;

		pinctrl-names = "switch1_act_switch2_act", "switch1_sleep_switch2_sleep",
						"switch1_act_switch3_act", "switch1_sleep_switch3_sleep",
						"switch1_act_switch2_sleep", "switch1_sleep_switch2_act",
						"clock_active","clock_sleep",
						"data_active","data_sleep",
						"reset_active","reset_sleep",
						"charging_switch1_ctr1_active","charging_switch1_ctr1_sleep";
		pinctrl-0 = <&charging_switch1_active>;
		pinctrl-1 = <&charging_switch1_sleep>;
		pinctrl-2 = <&charging_switch1_active>;
		pinctrl-3 = <&charging_switch1_sleep>;
		pinctrl-4 = <&charging_switch1_active>;
		pinctrl-5 = <&charging_switch1_sleep>;
		pinctrl-6 = <&charging_clock_active>;
		pinctrl-7 = <&charging_clock_sleep>;
		pinctrl-8 = <&charging_data_active>;
		pinctrl-9 = <&charging_data_sleep>;
		pinctrl-10 = <&charging_reset_active>;
		pinctrl-11 = <&charging_reset_sleep>;
		pinctrl-12 = <&charging_switch1_ctr1_active>;
		pinctrl-13 = <&charging_switch1_ctr1_sleep>;

		qcom,charging_switch1-gpio 		= <&pio 166 0x00>;
		qcom,charging_switch1_ctr1-gpio 	= <&pio 127 0x00>;
		//qcom,charging_switch2-gpio 		= <&tlmm 113 0x00>;
		//qcom,charging_switch3-gpio 		= <&tlmm 38 0x00>;

		qcom,charging_reset-gpio 			= <&pio 160 0x00>;
		qcom,charging_clock-gpio 			= <&pio 25 0x00>;
		qcom,charging_data-gpio 			= <&pio 26 0x00>;
	};

	stm8s_fastcg@26{
		status = "okay";
		compatible = "oplus,stm8s-fastcg";
		reg = <0x26 0>;
		qcom,vooc-low-temp = <120>;
		qcom,oplus_batt_4400mv;
		qcom,vooc_fw_update_newmethod;
		qcom,vooc-fw-type = <10>;

		pinctrl-names = "switch1_act_switch2_act", "switch1_sleep_switch2_sleep",
						"switch1_act_switch3_act", "switch1_sleep_switch3_sleep",
						"switch1_act_switch2_sleep", "switch1_sleep_switch2_act",
						"clock_active","clock_sleep",
						"data_active","data_sleep",
						"reset_active","reset_sleep";
		pinctrl-0 = <&charging_switch1_active>;
		pinctrl-1 = <&charging_switch1_sleep>;
		pinctrl-2 = <&charging_switch1_active>;
		pinctrl-3 = <&charging_switch1_sleep>;
		pinctrl-4 = <&charging_switch1_active>;
		pinctrl-5 = <&charging_switch1_sleep>;
		pinctrl-6 = <&charging_clock_active>;
		pinctrl-7 = <&charging_clock_sleep>;
		pinctrl-8 = <&charging_data_active>;
		pinctrl-9 = <&charging_data_sleep>;
		pinctrl-10 = <&charging_reset_active>;
		pinctrl-11 = <&charging_reset_sleep>;

		qcom,charging_switch1-gpio 		= <&pio 166 0x00>;
		//qcom,charging_switch2-gpio 		= <&tlmm 113 0x00>;
		//qcom,charging_switch3-gpio 		= <&tlmm 38 0x00>;

		qcom,charging_reset-gpio 			= <&pio 160 0x00>;
		qcom,charging_clock-gpio 			= <&pio 25 0x00>;
		qcom,charging_data-gpio 			= <&pio 26 0x00>;
	};
};
//#endif /* VENDOR_EDIT */

&pio {
	charging_switch1_ctr1_active: charging_switch1_ctr1_active {
		pins_cmd_dat {
			pinmux = <PINMUX_GPIO127__FUNC_GPIO127>;
			slew-rate = <1>;
			output-high;
		};
	};
	charging_switch1_ctr1_sleep: charging_switch1_ctr1_sleep {
		pins_cmd_dat {
			pinmux = <PINMUX_GPIO127__FUNC_GPIO127>;
			slew-rate = <1>;
			output-low;
		};
	};
	charging_switch1_active: charging_switch1_active {
		pins_cmd_dat {
			pinmux = <PINMUX_GPIO166__FUNC_GPIO166>;
			slew-rate = <1>;
			output-high;
		};
	};
	charging_switch1_sleep: charging_switch1_sleep {
		pins_cmd_dat {
			pinmux = <PINMUX_GPIO166__FUNC_GPIO166>;
			slew-rate = <1>;
			output-low;
		};
	};
	charging_clock_active: charging_clock_active {
		pins_cmd_dat {
			pinmux = <PINMUX_GPIO25__FUNC_GPIO25>;
			slew-rate = <0>;
			bias-pull-up = <00>;
		};
	};
	charging_clock_sleep: charging_clock_sleep {
		pins_cmd_dat {
			pinmux = <PINMUX_GPIO25__FUNC_GPIO25>;
			slew-rate = <0>;
			bias-pull-down = <00>;
		};
	};
	charging_data_active: charging_data_active {
		pins_cmd_dat {
			pinmux = <PINMUX_GPIO26__FUNC_GPIO26>;
			slew-rate = <0>;
			bias-pull-up = <00>;
		};
	};
	charging_data_sleep: charging_data_sleep {
		pins_cmd_dat {
			pinmux = <PINMUX_GPIO26__FUNC_GPIO26>;
			slew-rate = <0>;
			bias-pull-down = <00>;
		};
	};
	charging_reset_active: charging_reset_active {
		pins_cmd_dat {
			pinmux = <PINMUX_GPIO160__FUNC_GPIO160>;
			slew-rate = <1>;
			output-high;
		};
	};
	charging_reset_sleep: charging_reset_sleep {
		pins_cmd_dat {
			pinmux = <PINMUX_GPIO160__FUNC_GPIO160>;
			slew-rate = <1>;
			output-low;
		};
	};
};
&pio{
    gpio_goodix_reset_default: gpio_goodix_reset_default {
        pins_cmd_dat {
            pinmux = <PINMUX_GPIO43__FUNC_GPIO43>;
            output-low;
        };
    };
    gpio_goodix_irq_default: gpio_goodix_irq_default {
        pins_cmd_dat {
            pinmux = <PINMUX_GPIO10__FUNC_GPIO10>;
            bias-pull-down;
        };
    };
    //#ifdef VENDOR_EDIT
    gpio_goodix_clk_6mA: gpio_goodix_clk_6mA {
        pins_cmd_dat {
            pinmux = <PINMUX_GPIO88__FUNC_SPI0_CLK>;
            drive-strength = <2>;
        };
    };
    gpio_goodix_mosi_6mA: gpio_goodix_mosi_6mA {
        pins_cmd_dat {
            pinmux = <PINMUX_GPIO87__FUNC_SPI0_MO>;
            drive-strength = <2>;
        };
    };
    gpio_goodix_miso_6mA: gpio_goodix_miso_6mA {
        pins_cmd_dat {
            pinmux = <PINMUX_GPIO85__FUNC_SPI0_MI>;
            drive-strength = <3>;
        };
    };
    gpio_goodix_cs_6mA: gpio_goodix_cs_6mA {
        pins_cmd_dat {
            pinmux = <PINMUX_GPIO86__FUNC_SPI0_CSB>;
            drive-strength = <2>;
        };
    };
    gpio_goodix_clk_6mA_pulllow: gpio_goodix_clk_6mA_pulllow {
        pins_cmd_dat {
            pinmux = <PINMUX_GPIO88__FUNC_GPIO88>;
            output-low;
        };
    };
    gpio_goodix_mosi_6mA_pulllow: gpio_goodix_mosi_6mA_pulllow {
        pins_cmd_dat {
            pinmux = <PINMUX_GPIO87__FUNC_GPIO87>;
            output-low;
        };
    };
    gpio_goodix_miso_6mA_pulllow: gpio_goodix_miso_6mA_pulllow {
        pins_cmd_dat {
            pinmux = <PINMUX_GPIO85__FUNC_GPIO85>;
            output-low;
        };
    };
    gpio_goodix_cs_6mA_pulllow: gpio_goodix_cs_6mA_pulllow {
        pins_cmd_dat {
            pinmux = <PINMUX_GPIO86__FUNC_GPIO86>;
            output-low;
        };
    };
    gpio_goodix_cs_func: gpio_goodix_cs_func {
        pins_cmd_dat {
            pinmux = <PINMUX_GPIO86__FUNC_SPI0_CSB>;
            drive-strength = <2>;
        };
    };
    //#endif /*VENDOR_EDIT*/
};
//ifdef VENDOR_EDIT
&spi0 {
    #address-cells = <1>;
    #size-cells = <0>;
    status = "okay";
    oppo_fp: fingerprint@0 {
        compatible = "oppo,oppo_fp";
        reg = <0>;
        spi-max-frequency = <8000000>;
        spi-id = <0>;
        spi-irq = <10>;
        spi-reg = <11010000>;
        //avdd-supply = <&mt_pmic_vfp_ldo_reg>;
        status = "okay";
        pw_en_gpio = <&pio 176 0x00>;
        vddio_en = <&pio 151 0x00>;
        power_source_1 {
            power-mode = <2>;
            power-name = "pw_en_gpio";
            poweron-level = <1>;
            delay-time = <0>;
        };
        power_source_2 {
            power-mode = <2>;
            power-name = "vddio_en";
            poweron-level = <0>;
            delay-time = <0>;
        };
    };
};
//#endif /* VENDOR_EDIT */

&goodix_fp {
    goodix,gpio_irq = <&pio 10 0x00>;
    goodix,gpio_reset = <&pio 43 0x00>;
    //#ifdef VENDOR_EDIT
    goodix,pw_en = <&pio 176 0x00>;
    //goodix,vddio_en = <&pio 151 0x00>;
    //#endif /* VENDOR_EDIT */
    goodix,gpio_cs = <&pio 86 0x00>;
    pinctrl-names = "default", "gf_spi_drive_6mA", "gf_cs_func", "gf_spi_drive_6mA_pulllow";
    pinctrl-0 = <&gpio_goodix_irq_default>, <&gpio_goodix_reset_default>;
    pinctrl-1 = <&gpio_goodix_clk_6mA>, <&gpio_goodix_mosi_6mA>, <&gpio_goodix_miso_6mA>, <&gpio_goodix_cs_6mA>;
    pinctrl-2 = <&gpio_goodix_cs_func>;
    pinctrl-3 = <&gpio_goodix_clk_6mA_pulllow>, <&gpio_goodix_mosi_6mA_pulllow>, <&gpio_goodix_miso_6mA_pulllow>, <&gpio_goodix_cs_6mA_pulllow>;
    status = "okay";
};

//ifdef VENDOR_EDIT
/*the id config to project dts.*/
&pio{
	gpio_id0_default: gpio_id0_default {
		pins_cmd_dat {
			pinmux = <PINMUX_GPIO19__FUNC_GPIO19>;
			bias-pull-up = <00>;
			input-enable;
		};
	};
};

&oplus_fp_common {
	compatible = "oplus,fp_common"; //Manufacture, and Model
	oplus,fp_gpio_num = <1>;
	oplus,fp_gpio_0 = <&pio 19 0x00>;
	pinctrl-names = "default";
	pinctrl-0 = <&gpio_id0_default>;
	goodix_id {
		oplus,fp-id = <1>; /* fp id mapping table */
		vendor-chip = <11>; /* please refer to the struct fp_vendor_t in oppo_fp_commmon.n */
		eng-menu = "-1,-1"; /* represents SNR, inclination test item in engineer menu, and 0/1 means off/on */
		chip-name = "G_OPTICAL_G3";  /* /proc/fp_id, will be displayed in engineer menu  */
	};
	egis_id {
		oplus,fp-id = <0>; /* fp id mapping table */
		vendor-chip = <15>; /* please refer to the struct fp_vendor_t in oppo_fp_commmon.n */
		eng-menu = "-1,-1"; /* represents SNR, inclination test item in engineer menu, and 0/1 means off/on */
		chip-name = "E_OPTICAL_ET713";  /* /proc/fp_id, will be displayed in engineer menu  */
	};
};

#include <oppo6771_19350/cust.dtsi>
//#include "cust_mt6771_camera.dtsi"
/*End of this file, DO NOT ADD ANYTHING HERE*/


